# M3351 register map
File version: 1.0
Registers are 32-bit, read-write, reset 0x0 unless marked. A register's access mark holds for its fields unless they carry their own. Offsets are from the block's base; [hi:lo] are bit positions.

## I3C0 (part 1 of 2) — I3C Register Map
Base 0x40086000
Same registers: I3C0_NS 0x50086000
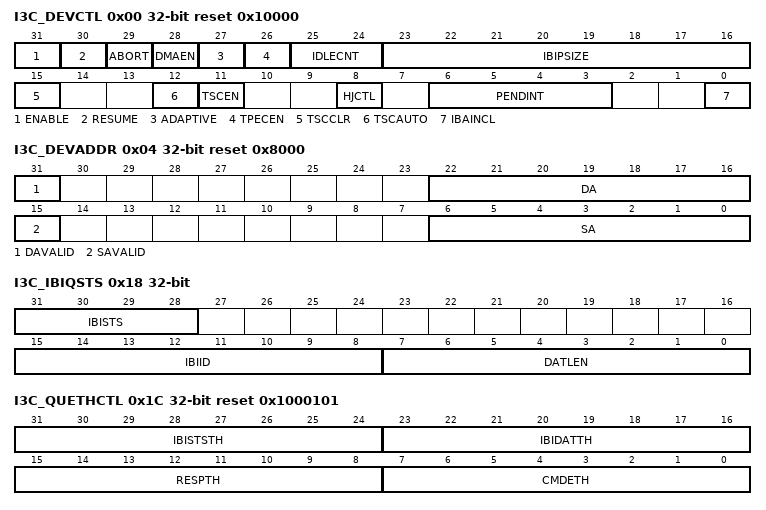
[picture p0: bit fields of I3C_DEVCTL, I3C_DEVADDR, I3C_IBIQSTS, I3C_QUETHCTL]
0x00 I3C_DEVCTL reset 0x10000 — I3C Device Control Register
  [31] ENABLE — Controls whether or not I3C is Enabled. Note 1: To Enable the Target controller, the application must set the ENABLE bit to 1. Enabling the Target controller might not be instantaneous because it is dependent on the availability of SCL clock on the I3C line. Note 2: To Disable the Target controller, the application after setting the value of 0 to the ENABLE bit must keep polling the ENABLE bit to check whether the bit value is zero. Note 3: Once the ENABLE bit is read with a value of zero, the application can be sure that the Target controller is disabled. If the SCL clock is present, the Target controller takes two SCL clocks to come out of the Disable state.
    0=I3C controller Disabled; 1=I3C controller Enabled
  [30] RESUME — I3C Resume Bit. This bit is used to resume the Controller/Target after it goes to the halt state. Note 1: In the Controller mode of operation, the Controller goes to the halt state due to any type of error in the transfer. After the Controller gones to the halt state, the application has to write 1'b1 to this bit to resume the Controller. This bit is auto-cleared once the Controller resumes the transfers by initiating the next command. Note 2: In the Target mode of operation, the Target goes to the halt state due to following conditions: Any type of error in the transfer. MRL in I3C_SLVMXLEN[31:16] updated by the controller through SETMRL CCC. After the Target goes to the halt state, the application has to take necessary action to handle the error condition and then write 1'b1 to this bit to resume the Target. This bit is auto-cleared once the Target is ready to accept new transfers (If Target has Protocol Error, RESUME bit cannot auto-clear until GETSTATS CCC is received).
    0=Resume operation is completion; 1=Resume operation is in progress
  [29] ABORT — Abort Controller Operation. This bit is used in Controller mode of operation. This bit allows the Controller to relinquish the I3C bus before completing the issued transfer In response to an ABORT request, the Controller issues the STOP condition after the complete data byte is transferred or received. This bit is auto-cleared once the transfer is aborted and the Controller issues a 'Transfer Abort' interrupt (I3C_INTSTS[5]).
    0=No effect; 1=Trigger ABORT request
  [28] DMAEN — DMA Handshake Interface Enable
    0=The DMA handshake control has no significance; 1=Enables the DMA handshake control to interact with external DMA
  [27] ADAPTIVE — Adaptive Mode. This bit is used in Target mode of operation. Setting of this bit is NOT required to put the Target in Adaptive Mode. It is only used to enable some features of the Target device to adapt to Adaptive I2C/I3C mode of operation. This bit is cleared automatically if the Target determines the mode as I3C. Effect on Hot-Join operation:
    0=The Target initiates a Hot- Join without determining the bus mode assuming itself to be on i3c bus. This bit should be set only if the Target application does not know to which bus the device is connected to.; 1=The Target initiates a Hot-Join request only after it has switched to I3C mode of operation
  [26] TPECEN — Target Packet Error Check Enable Bit. Target application to enable Packet Error Check. The user programs this bit before enabling the Target.
    0=PEC support is Disabled; 1=PEC support is Enabled
  [25:24] IDLECNT — Idle Count Multiplier. This field is used in Target mode of operation. After power-on reset, the Target device is enabled only after it sees both SDA and SCL lines idle for a specified time. This idle time is calculated by multiplying IDLECNT with AVAILTC field in BUSFAT[31:16].
  [23:16] IBIPSIZE — Target Maximum IBI Payload Size. This value reflects the I3C Target IBI Payload Size if the Controller sends a GETMRL/SETMRL CCC. Note: This field is read only.
  [15] TSCCLR — Timestamp Counter Clear Bit. This bit is used in Controller mode of operation. Note: This bit is cleared by hardware automatically.
    0=Clear timestamp counter Disabled; 1=Clear Clear timestamp counter Enabled
  [12] TSCAUTO — Timestamp Counter Automatic Enable Bit. This bit is used in Target mode of operation. When SIR is Enabled, Timestamp Counter will be cleared and restarted.
    0=Timestamp Counter automatic Disabled; 1=Timestamp Counter automatic Enabled
  [11] TSCEN — Timestamp Counter Enable Bit. This bit is used in Controller mode of operation.
    0=Timestamp counter Disabled; 1=Timestamp counter Enabled
  [8] HJCTL — Hot-Join ACK/NACK Control. This bit is used in Controller mode of operation. This bit acts as a global control to ACK/NACK the Hot-Join request from the devices. The I3C Controller ACK/NACKs the Hot-Join request from other devices connected on the I3C bus, based on programming of this bit.
    0=ACK the Hot-join request; 1=NACK and send broadcast DISEC CCC to disable Hot-Join of Target devices
  [6:3] PENDINT — Pending Interrupt Status. This field is used in Target mode of operation. This field is used for setting the interrupt number and is also reflected in I3C_CCCDEVS[3:0] PENDINT.
  [0] IBAINCL — I3C Broadcast Address Include. This bit is used in Controller mode of operation. Note: If I3C broadcast address is not included for the private transfers, In-Band Interrupts (IBI) driven from Targets might not win address arbitration. Hence, the IBIs get delayed.
    0=I3C Broadcast Address (0x7E) is not included for Private Transfer; 1=I3C Broadcast Address (0x7E) is included for Private Transfers
0x04 I3C_DEVADDR reset 0x8000 — I3C Device Address Register
  [31] DAVALID — Dynamic Address Valid. In I3C Controller mode, the user sets this bit to 1 as it self-assigns its dynamic address. In I3C Target mode, this bit will be set to 1 when the Main Controller assigns the dynamic address during ENTDAA, SETDASA or SETAASA mechanism. Note: This bit can be auto-clear to 0 if RSTDAA CCC is reveived.
    0=I3C Dynamic Address is invalid; 1=I3C Dynamic Address is valid
  [22:16] DA — Device Dynamic Address. In Controller mode, the user has to program the Dynamic Address through the Target interface as it self-assigns its Dynamic Address. In Target mode, this field is used to indicate the device Dynamic Address after Target completes the dynamic address assignment operation by ENTDAA, SETDASA, SETAASA or SETNEDA CCC.
  [15] SAVALID — Static Address Valid. In Target mode of operation, this bit reflects whether the value of the static address is valid or not.
    0=Static Address is invalid; 1=Static Address is valid
  [6:0] SA — Device Static Address. The Target device uses this address to respond to SETDASA or SETAASA CCC to get the Dynamic Address or performs Legacy I2C Read/Write operation.
0x0C I3C_CMDQUE wo — I3C Command Queue Port Register
  [31:0] CMDQUE — Command Queue. This field is used in Controller mode of operation. Please refer to chapter Controller Command Data Structure.
0x10 I3C_RESPQUE ro — I3C Response Queue Port Register
  [31:0] RESPQUE — Response Queue. Please refer to chapter Controller Response Data Structure and chapter Extended Response Data Structure.
0x14 I3C_TXRXDAT — I3C Transmit and Receive Data Port Register
  [31:0] DAT — Transmit and Receive Data Port. Transmit (Write) Operation: The transmit operation is used in Controller mode of operation. The Transmit Data port is mapped to the Tx-Data Buffer. The transmit data should always be packed as 4-byte aligned data words and written to the Transmit Data Port register. If the Command length is not aligned to 4-bytes, then the additional bytes are ignored. Receive (Read) Operation: The receive operation is used in both Controller mode and Target mode. The Receive Data port is mapped to the Rx-Data Buffer. The receive data is always packed in 4-byte aligned data words and stored in the Rx-Data Buffer. If the command length is not aligned to the 4-bytes, then the additional data bytes have to be ignored.
0x18 I3C_IBIQSTS ro — I3C Controller In-Band Interrupt Queue Status Register
  [31:28] IBISTS — IBI Received Status. Defines the Controller response for IBI received.
  [15:8] IBIID — IBI Identifier. The byte received after START which includes the address and the R/W bit. Device address and R/W bit in case of Target Interrupt or Controller Request. Hot-Join ID (0x2) and R/W bit in case of Hot-Join request.
  [7:0] DATLEN — In-Band Interrupt Data Length. This field represents the length of data received along with the IBI, in bytes.
0x18 I3C_IBIQUE ro (alternate view of I3C_IBIQSTS) — I3C Controller In-Band Interrupt Queue Data Register
  [31:0] IBIDAT — In-Band Interrupt Data. This register when read from, reads the data from the IBI Queue. This register is mapped to the IBI Queue. The IBI Data is always packed in 4-byte aligned and put to the IBI Queue. If the incoming data is not aligned to the 4-bytes, then there are unused bytes in the end location of the IBI transfer.
0x1C I3C_QUETHCTL reset 0x1000101 — I3C Queue Threshold Control Register
  [31:24] IBISTSTH — In-Band Interrupt Status Threshold Value. Every In-Band Interrupt received by I3C Controller generates an IBI status. The valid range is 0 to 3. This field controls the number of IBI status entries (or greater) in the IBI queue that trigger the IBITH (I3C_INTSTS[2]) interrupt. The user programs only valid values. A value of 0 sets the threshold for 1 entry, and a value of N sets the threshold for N+1 entries.
  [23:16] IBIDATTH — IBI Data Threshold Value. This field represents the IBI data segment size in DWORDS, 4 bytes. The valid range is 0 to 15. The minimum supported segment size is 1 (4 bytes) and the maximum supported size is 16 (64 bytes). The IBIDATTH field enables the slicing of the incoming IBI data and generate individual status and thereby promotes the cut-through operation in reading out the IBI data.
  [15:8] RESPTH — Response Buffer Threshold Value. Controls the number of entries (or greater) in the Response Queue that trigger the RESPRDY (I3C_INTSTS[4]) interrupt. The valid range is 0 to 3. The user programs only valid values. A value of 0 sets the threshold for 1 entry, and a value of N sets the threshold for N+1 entries.
  [7:0] CMDETH — Command Buffer Empty Threshold Value. Controls the number of empty locations (or greater) in the Command Queue that trigger CMDRDY (I3C_INTSTS[3]) interrupt. The valid range is 0 to 7. The user programs only valid values. Value of N ranging from 1 to 7 sets the threshold to N empty locations and a value of 0 sets the threshold to indicate that the queue is completely empty.
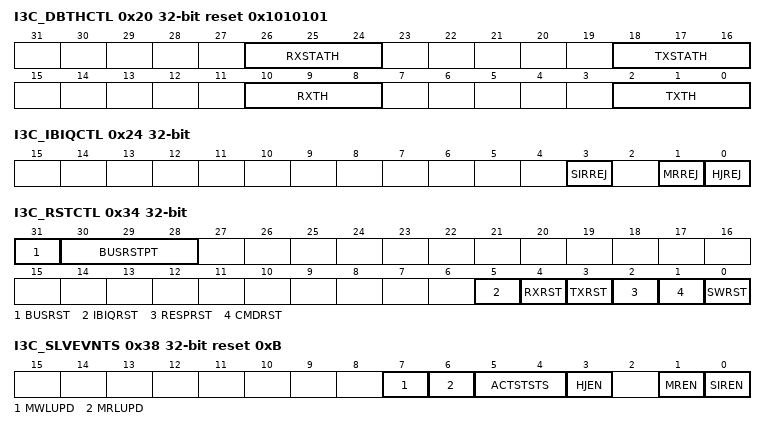
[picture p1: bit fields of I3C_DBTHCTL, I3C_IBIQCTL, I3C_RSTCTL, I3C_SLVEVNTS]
0x20 I3C_DBTHCTL reset 0x1010101 — I3C Data Buffer Threshold Control Register
  [26:24] RXSTATH — Receive Start Threshold Value. In Controller mode of operation. When the Controller is set up to initiate a read transfer, it waits until either one of the conditions are met before it initiates the read transfer on the I3C Interface. Data length (as specified in the command) number of locations are empty in the Receive FIFO. Threshold number of locations (or more) are empty in the Receive FIFO. In Target mode of operation. The Target ACK's a write request from Controller only if threshold number of empty locations (or more) are available in its receive buffer. The supported values for RXSTATH are: Note: Unit in DWORDS, 4 bytes.
  [18:16] TXSTATH — Transfer Start Threshold Value. In Controller mode of operation. When the Controller is set up to initiate a write transfer, it waits until either one of the following conditions are met before it initiates the write transfer on the I3C Interface. Data length (as specified in the command) number of locations are filled in the Transmit FIFO. Threshold number of entries (or more) are available in the Transmit FIFO. In Target mode of operation. The Target ACK's a read request from Controller only if either one of the following conditions are met: Data length (as specified in the command) number of locations are filled in the Transmit FIFO. Threshold number of entries (or more) are available in the Transmit FIFO. The supported values for TXSTATH are: Note: Unit in DWORDS, 4 bytes.
  [10:8] RXTH — Receive Buffer Threshold Value. This field controls the number of entries (or above) in the Receive FIFO that trigger the RXTH (I3C_INTSTS[1]) interrupt. The supported values for RXTH are: Note: Unit in DWORDS, 4 bytes.
  [2:0] TXTH — Transmit Buffer Threshold Value. This field controls the number of empty locations (or above) in the Transmit FIFO that trigger the TXTH (I3C_INTSTS[0]) interrupt. The supported values for TXTH are: Note: Unit in DWORDS, 4 bytes.
0x24 I3C_IBIQCTL — I3C Controller In-Band Interrupt Queue Control Register
  [3] SIRREJ — Notify Rejected Target Interrupt Request Control. This bit is used to suppress reporting to the application about SIR request rejected.
    0=Notify SIR Rejected Disabled; 1=Notify SIR Rejected Enabled
  [1] MRREJ — Notify Rejected Controller Request Control. This bit is used to suppress reporting to the application about Controller request rejected.
    0=Notify Controller Request Rejected Disabled; 1=Notify Controller Request Rejected Enabled
  [0] HJREJ — Notify Rejected Hot-Join Request Control. This bit is used to suppress reporting to the application about Hot-Join request rejected.
    0=Notify Hot-Join Request Rejected Disabled; 1=Notify Hot-Join Request Rejected Enabled
0x34 I3C_RSTCTL — I3C Reset Control Register
  [31] BUSRST — Bus Reset. This bit is used in Controller mode of operation. Note: This bit is cleared automatically once the Bus Reset Pattern Generation is completed.
    0=No effect; 1=Perform Bus Reset Pattern Generation based on Bus Reset Type (BUSRSTY) selection
  [30:28] BUSRSTPT — Bus Reset Pattern Type. This field is used in Controller mode of operation. Type of bus reset pattern triggered by BUSRST.
  [5] IBIQRST — IBI Queue Software Reset. This bit is used in Controller mode of operation. Note: This bit is cleared automatically once the IBI Queue reset is completed.
    0=No effect; 1=Perform IBI Queue reset
  [4] RXRST — Receive Buffer Software Reset. Note: This bit is cleared automatically once the Receive buffer reset is completed.
    0=No effect; 1=Perform Receive Buffer reset
  [3] TXRST — Transmit Buffer Software Reset. Note: This bit is cleared automatically once the Transmit Buffer reset is completed.
    0=No effect; 1=Perform Transmit Buffer reset
  [2] RESPRST — Response Queue Software Reset. Note: This bit is cleared automatically once the Response Queue reset is completed.
    0=No effect; 1=Perform Response Queue reset
  [1] CMDRST — Command Queue Software Reset. Note: This bit is cleared automatically once the Command Queue reset is completed.
    0=No effect; 1=Perform Command Queue reset
  [0] SWRST — Core Software Reset. This reset: The Queues and Buffers. User programmable registers to reflect the Reset values. Pipelining data (if any). The state machine to Idle state. Note: This bit is cleared automatically once the core reset is completed.
    0=No effect; 1=Perform Software reset
0x38 I3C_SLVEVNTS reset 0xB — I3C Target Event Status Register
  [7] MWLUPD — MWL Updated Status. This bit indicates a SETMWL CCC is received by the Target. The updated MWL value can be read from MWL (I3C_SLVMXLEN[15:0]). Note: This bit is cleared by writing 1 to it.
    0=SETMWL CCC not Received; 1=SETMWL CCC Received
  [6] MRLUPD — MRL Updated Status. This bit indicates a SETMRL CCC is received by the Target. The updated MRL value can be read from MRL (I3C_SLVMXLEN[31:16]). Note: This bit is cleared by writing 1 to it.
    0=SETMRL CCC not Received; 1=SETMRL CCC Received
  [5:4] ACTSTSTS — Activity State Status. This field reflects the Activity State of the Target set by the Controller. Note: This field is read only.
  [3] HJEN — Hot-Join Request Interrupt Enable Bit. This bit reflects whether the Hot-Join Request Interrupts are allowed on the I3C bus or not. The Target application can choose to Disable HJ Capability of the Target (if selected) by setting this bit to 0 before 'Enabling' the Target device. When done so, the Target does not initiate Hot-Join request and takes part in Address Assignment without initiating Hot-Join. If this bit is NOT set to 0 by Target application, it can be set or cleared by the I3C Controller through ENEC or DISEC CCC. Once Disabled by software, CCCs do not have any effect on this field.
    0=Hot-Join Request Interrupt function Disabled; 1=Hot-Join Request Interrupt function Enabled
  [1] MREN — Controller Request Enable Bit. This bit reflects whether the Target can initiate the Controller Request on the I3C bus or not. Usually, this bit is set or cleared by the I3C Controller through ENEC or DISEC CCC. Note: This bit is read only.
    0=Controller Request function Disabled; 1=Controller Request function Enabled
  [0] SIREN — Target Interrupt Request Enable Bit. This bit reflects whether the Target can initiate the SIR on the I3C bus or not. Usually, this bit is set or cleared by the I3C Controller through ENEC or DISEC CCC. Note: This bit is read only.
    0=Target Interrupt Request function Disabled; 1=Target Interrupt Request function Enabled
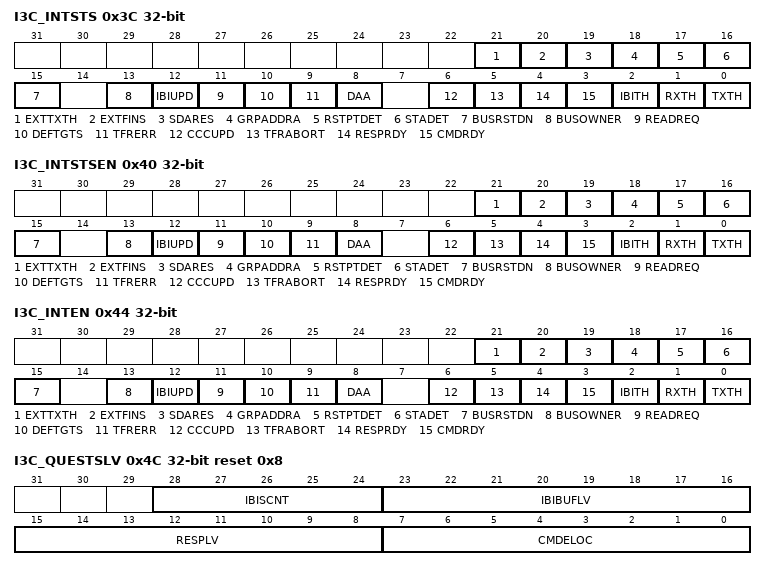
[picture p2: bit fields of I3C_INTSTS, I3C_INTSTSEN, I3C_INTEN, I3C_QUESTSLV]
0x3C I3C_INTSTS — I3C Interrupt Status Register
  [21] EXTTXTH — EXTCMD Transmit Buffer Threshold Status. This bit is used in Target mode of operation. Note 1: This bit is read only. Note 2: This bit is cleared automatically when number of empty locations in all the EXTCMD transmit buffers is less than threshold value specified.
    0=The number of EXTCMD transmit buffer empty locations is less than threshold value TXEBTH (I3C_EXTTHLD[18:16]); 1=The number of EXTCMD transmit buffer empty locations is greater than or equal to threshold value TXEBTH (I3C_EXTTHLD[18:16])
  [20] EXTFINS — EXTCMD Has Finished Status. This bit is used in Target mode of operation. This bit is generated if Read Transfer has finished (I3C_EXTCMDFS[7:0] not equal to 0) by the EXTCMD. Note 1: This bit is read only. Note 2: This bit is cleared automatically when I3C_EXTCMDFS register is read.
    0=No EXTCMD finished the transfer. (I3C_EXTCMDFS[7:0] is equal to 0); 1=EXTCMD Read Transfer has finished. (I3C_EXTCMDFS[7:0] is not equal to 0)
  [19] SDARES — SDA Released From Stuck State Status. This bit is used in Target mode of operation. This bit is generated if the SCL was not changed for the prescribed amount of time defined by RELSDATC (I3C_RELSDA[19:0]). Note: This bit is cleared by writing 1 to it.
    0=Bus in Idle state; 1=SDA status is released from stuck state
  [18] GRPADDRA — Group Address Assigned Status. This bit is used in Target mode of operation. This bit is generated if one of the Target's Group Address is assigned through SETGRPA CCC or reset through RSTGRPA CCC. Note: This bit is cleared by writing 1 to it.
    0=Group Address Assigned status no Changed; 1=Group Address Assigned status Changed
  [17] RSTPTDET — Target Reset Pattern Detection Status. This bit is used in Target mode of operation. This bit is generated when the Target Reset Pattern is detected. Note: This bit is cleared by writing 1 to it.
    0=Target Reset Pattern no Detected; 1=Target Reset Pattern Detected
  [16] STADET — START Detection Status. This bit is used in Target mode of operation. This bit is provided for the Target application to determine whether a START signal is detected on the bus. Note: This bit is cleared by writing 1 to it.
    0=START signal no Detected; 1=START signal Detected
  [15] BUSRSTDN — Bus Reset Pattern Generation Done Status. This bit is used in Controller mode of operation. This bit is generated when the Bus Reset Pattern Generation is completed. Note: This bit is cleared by writing 1 to it.
    0=Bus Reset Pattern Generation is not complete; 1=Bus Reset Pattern Generation is complete
  [13] BUSOWNER — Bus Owner Updated Status. This bit is set when the role of the device changes from being a Controller to Target or vice versa. Note 1: This bit is cleared by writing 1 to it. Note 2: The new Bus Owner value is updated only if the device's RESUME (I3C_DEVCTL[30]) bit is set.
    0=Bus Owner status is not changed; 1=Bus Owner status is changed
  [12] IBIUPD — IBI Status Updated Status. This bit is used in Target mode of operation. It indicates that the IBI request initiated through SIR register is addressed and status is updated. Note: This bit is cleared by writing 1 to it.
    0=IBI status is not updated; 1=IBI status is updated
  [11] READREQ — Read Request Received Status. This bit is used in Target mode of operation. Read Request received from the current Controller when EXTCMD is empty. Note: This bit is cleared by writing 1 to it.
  [10] DEFTGTS — DEFTGTS CCC Received Status. This bit is used in Secondary Controller mode of operation. Note: This bit is cleared by writing 1 to it.
    0=DEFTGTS (DEFSLVS) CCC is not received; 1=DEFTGTS (DEFSLVS) CCC is received
  [9] TFRERR — Transfer Error Status. This bit is generated if any error occurs during transfer. The error type is specified in the response packet associated with the command, ERRSTS field in Response Quene Port register. In Controller mode of operation, ERRSTS in I3C_RESPQUE[31:28]. In Target mode of operation, ERRSTS in I3C_RESPQUE[11:8]. Note: This bit is cleared by writing 1 to it.
    0=Transfer error is not occurred; 1=Transfer error occurred
  [8] DAA — Dynamic Address Assigned Status. This bit is used in Target mode of operation. This bit is generated if the Target Dynamic Address is assigned through ENTDAA, SETDASA, SETNEWDA or SETAASA CCC. Note: This bit is cleared by writing 1 to it.
    0=Dynamic Address is not assigned; 1=Dynamic Address is assigned
  [6] CCCUPD — CCC Table Updated Status. This bit is used in Target mode of operation. This bit is generated if any of the CCC registers are updated by I3C Controller through CCC commands. Note: This bit is cleared by writing 1 to it.
    0=Related CCC registers are not updated; 1=Related CCC registers are updated
  [5] TFRABORT — Transfer Abort Status. This bit is used in Controller mode of operation. This bit is generated if transfer is aborted. Note: This bit is cleared by writing 1 to it.
    0=Transfer is not aborted; 1=Transfer is aborted
  [4] RESPRDY — Response Queue Ready Status. This bit is generated when number of entries in response queue is greater than or equal to threshold value specified by RESPTH (I3C_QUETHCTL[15:8]). Note 1: This bit is read only. Note 2: This bit is cleared automatically when number of entries in response buffer is less than threshold value specified.
    0=Response Queue is not ready; 1=Response Queue is ready
  [3] CMDRDY — Command Queue Ready Status. This bit is used in Controller mode of operation. This bit is generated when number of empty locations in command queue is greater than or equal to threshold value specified by CMDETH (I3C_QUETHCTL[7:0]). Note 1: This bit is read only. Note 2: This bit is cleared automatically when number of empty locations in command buffer is less than threshold value specified.
    0=Command Queue is not ready; 1=Command Queue is ready
  [2] IBITH — IBI Buffer Threshold Status. This bit is used in Controller mode of operation. This bit is generated when number of entries in IBI buffer is greater than or equal to threshold value specified by IBISTSTH (I3C_QUETHCTL[31:24]). Note 1: This bit is read only. Note 2: This bit is cleared automatically when number of entries in IBI buffer is less than threshold value specified.
    0=IBI buffer is not ready; 1=IBI buffer is ready
  [1] RXTH — Receive Buffer Threshold Status. This bit is generated when number of entries in receive buffer is greater than or equal to threshold value specified by RXTH (I3C_DBTHCTL[10:8]). Note 1: This bit is read only. Note 2: This bit is cleared automatically when number of entries in receive buffer is less than threshold value specified.
    0=The number of receive buffer is less than to threshold value specified by RXTH; 1=The number of receive buffer is greater than or equal to threshold value specified by RXTH
  [0] TXTH — Transmit Buffer Threshold Status. This bit is generated when the number of empty locations in transmit buffer is greater than or equal to threshold value specified by TXTH (I3C_DBTHCTL[2:0]). Note 1: This bit is read only. Note 2: This bit is cleared automatically when number of empty locations in transmit buffer is less than threshold value specified.
    0=The number of receive buffer is less than to threshold value specified by TXTH; 1=The number of receive buffer is greater than or equal to threshold value specified by TXTH
0x40 I3C_INTSTSEN — I3C Interrupt Status Enable Register
  [21] EXTTXTH — EXTCMD Transmit Buffer Threshold Status Enable Bit. This bit is used in Target mode of operation.
    0=EXTCMD Transmit Buffer Threshold Status Disabled; 1=EXTCMD Transmit Buffer Threshold Status Enabled
  [20] EXTFINS — EXTCMD Has Finished Status Enable Bit. This bit is used in Target mode of operation.
    0=EXTCMD Has Finished Status Disabled; 1=EXTCMD Has Finished Status Enabled
  [19] SDARES — SDA Released From Stuck Status Enable Bit. This bit is used in Target mode of operation.
    0=SDA Released From Stuck Status Disabled; 1=SDA Released From Stuck Status Enabled
  [18] GRPADDRA — Group Address Assigned Status Enable Bit. This bit is used in Target mode of operation.
    0=Group Address Assigned Status Disabled; 1=Group Address Assigned Status Enabled
  [17] RSTPTDET — Target Reset Pattern Detection Status Enable Bit. This bit is used in Target mode of operation.
    0=Target Reset Pattern Detection Status Disabled; 1=Target Reset Pattern Detection Status Enabled
  [16] STADET — START Detection Status Enable Bit. This bit is used in Target mode of operation.
    0=START Detection Status Disabled; 1=START Detection Status Enabled
  [15] BUSRSTDN — Bus Reset Pattern Generation Done Status Enable Bit. This bit is used in Controller mode of operation.
    0=Bus Reset Pattern Generation Done Status Disabled; 1=Bus Reset Pattern Generation Done Status Enabled
  [13] BUSOWNER — Bus Owner Updated Status Enable Bit. This bit is used in both Controller and Target mode of operation.
    0=Bus Owner Updated Status Disabled; 1=Bus Owner Updated Status Enabled
  [12] IBIUPD — IBI Updated Status Enable Bit. This bit is used in Target mode of operation.
    0=IBI Updated Status Disabled; 1=IBI Updated Status Enabled
  [11] READREQ — Read Request Received Status Enable Bit. This bit is used in Target mode of operation.
    0=Read Request Received Status Disabled; 1=Read Request Received Status Enabled
  [10] DEFTGTS — DEFTGTS CCC Received Status Enable Bit. This bit is used in Secondary Controller mode of operation.
    0=DEFTGTS CCC Received Status Disabled; 1=DEFTGTS CCC Received Status Enabled
  [9] TFRERR — Transfer Error Status Enable Bit. This bit is used in both Controller and Target mode of operation.
    0=Transfer Error Status Disabled; 1=Transfer Error Status Enabled
  [8] DAA — Dynamic Address Assigned Status Enable Bit. This bit is used in Target mode of operation.
    0=Dynamic Address Assigned Status Disabled; 1=Dynamic Address Assigned Status Enabled
  [6] CCCUPD — CCC Table Updated Status Enable Bit. This bit is used in Target mode of operation.
    0=CCC Table Updated Status Disabled; 1=CCC Table Updated Status Enabled
  [5] TFRABORT — Transfer Abort Status Enable Bit. This bit is used in Controller mode of operation.
    0=Transfer Abort Updated Status Disabled; 1=Transfer Abort Updated Status Enabled
  [4] RESPRDY — Response Queue Ready Status Enable Bit. This bit is used in both Controller and Target mode of operation.
    0=Response Queue Ready Status Disabled; 1=Response Queue Ready Status Enabled
  [3] CMDRDY — Command Queue Ready Status Enable Bit. This bit is used in Controller mode of operation.
    0=Command Queue Ready Status Disabled; 1=Command Queue Ready Status Enabled
  [2] IBITH — IBI Buffer Threshold Status Enable Bit. This bit is used in Controller mode of operation.
    0=IBI Buffer Threshold Status Disabled; 1=IBI Buffer Threshold Status Enabled
  [1] RXTH — Receive Buffer Threshold Status Enable Bit. This bit is used in both Controller and Target mode of operation.
    0=Receive Buffer Threshold Status Disabled; 1=Receive Buffer Threshold Status Enabled
  [0] TXTH — Transmit Buffer Threshold Status Enable Bit. This bit is used in both Controller and Target mode of operation.
    0=Transmit Buffer Threshold Status Disabled; 1=Transmit Buffer Threshold Status Enabled
0x44 I3C_INTEN — I3C Interrupt Signal Enable Register
  [21] EXTTXTH — EXTCMD Transmit Buffer Threshold Signal Enable Bit. This bit is used in Target mode of operation.
    0=EXTCMD Transmit Buffer Threshold Interrupt Disabled; 1=EXTCMD Transmit Buffer Threshold Interrupt Enabled
  [20] EXTFINS — EXTCMD Has Finished Signal Enable Bit. This bit is used in Target mode of operation.
    0=EXTCMD Has Finished Interrupt Disabled; 1=EXTCMD Has Finished Interrupt Enabled
  [19] SDARES — SDA Released From Stuck Signal Enable Bit. This bit is used in Target mode of operation.
    0=SDA Released From Stuck Interrupt Disabled; 1=SDA Released From Stuck Interrupt Enabled
  [18] GRPADDRA — Group Address Assigned Signal Enable Bit. This bit is used in Target mode of operation.
    0=Group Address Assigned Interrupt Disabled; 1=Group Address Assigned Interrupt Enabled
  [17] RSTPTDET — Target Reset Pattern Detection Signal Enable Bit. This bit is used in Target mode of operation.
    0=Target Reset Pattern Detection Interrupt Disabled; 1=Target Reset Pattern Detection Interrupt Enabled
  [16] STADET — START Detection Signal Enable Bit. This bit is used in Target mode of operation.
    0=START Detection Interrupt Disabled; 1=START Detection Interrupt Enabled
  [15] BUSRSTDN — Bus Reset Pattern Generation Done Signal Enable Bit. This bit is used in Controller mode of operation.
    0=Bus Reset Pattern Generation Done Interrupt Disabled; 1=Bus Reset Pattern Generation Done Interrupt Enabled
  [13] BUSOWNER — Bus Owner Updated Signal Enable Bit. This bit is used in both Controller and Target mode of operation.
    0=Bus Owner Updated Interrupt Disabled; 1=Bus Owner Updated Interrupt Enabled
  [12] IBIUPD — IBI Updated Signal Enable Bit. This bit is used in Target mode of operation.
    0=IBI Updated Interrupt Disabled; 1=IBI Updated Interrupt Enabled
  [11] READREQ — Read Request Received Signal Enable Bit. This bit is used in Target mode of operation.
    0=Read Request Received Interrupt Disabled; 1=Read Request Received Interrupt Enabled
  [10] DEFTGTS — DEFTGTS CCC Received Signal Enable Bit. This bit is used in Secondary Controller mode of operation.
    0=DEFTGTS CCC Received Interrupt Disabled; 1=DEFTGTS CCC Received Interrupt Enabled
  [9] TFRERR — Transfer Error Signal Enable Bit. This bit is used in both Controller and Target mode of operation.
    0=Transfer Error Interrupt Disabled; 1=Transfer Error Interrupt Enabled
  [8] DAA — Dynamic Address Assigned Signal Enable Bit. This bit is used in Target mode of operation.
    0=Dynamic Address Assigned Interrupt Disabled; 1=Dynamic Address Assigned Interrupt Enabled
  [6] CCCUPD — CCC Table Updated Signal Enable Bit. This bit is used in Target mode of operation.
    0=CCC Table Updated Interrupt Disabled; 1=CCC Table Updated Interrupt Enabled
  [5] TFRABORT — Transfer Abort Signal Enable Bit. This bit is used in Controller mode of operation.
    0=Transfer Abort Interrupt Disabled; 1=Transfer Abort Interrupt Enabled
  [4] RESPRDY — Response Queue Ready Signal Enable Bit. This bit is used in both Controller and Target mode of operation.
    0=Response Queue Ready Interrupt Disabled; 1=Response Queue Ready Interrupt Enabled
  [3] CMDRDY — Command Queue Ready Signal Enable Bit. This bit is used in Controller mode of operation.
    0=Command Queue Ready Interrupt Disabled; 1=Command Queue Ready Interrupt Enabled
  [2] IBITH — IBI Buffer Threshold Signal Enable Bit. This bit is used in Controller mode of operation.
    0=IBI Buffer Threshold Interrupt Disabled; 1=IBI Buffer Threshold Interrupt Enabled
  [1] RXTH — Receive Buffer Threshold Signal Enable Bit. This bit is used in both Controller and Target mode of operation.
    0=Receive Buffer Threshold Interrupt Disabled; 1=Receive Buffer Threshold Interrupt Enabled
  [0] TXTH — Transmit Buffer Threshold Signal Enable Bit. This bit is used in both Controller and Target mode of operation.
    0=Transmit Buffer Threshold Interrupt Disabled; 1=Transmit Buffer Threshold Interrupt Enabled
0x4C I3C_QUESTSLV ro reset 0x8 — I3C Queue Status Level Register
  [28:24] IBISCNT — IBI Status Count. This bit is used in Controller mode of operation. Contains the number of valid IBI Status entries in the IBI Status Buffer.
  [23:16] IBIBUFLV — IBI Buffer Level Value. This bit is used in Controller mode of operation. Contains the number of valid IBI Data entries in the IBI Data Buffer.
  [15:8] RESPLV — Response Buffer Level Value. Contains the number of valid data entries in the Response Buffer.
  [7:0] CMDELOC — Command Queue Empty Locations. This bit is used in Controller mode of operation. Contains the number of empty locations in the Command Buffer.
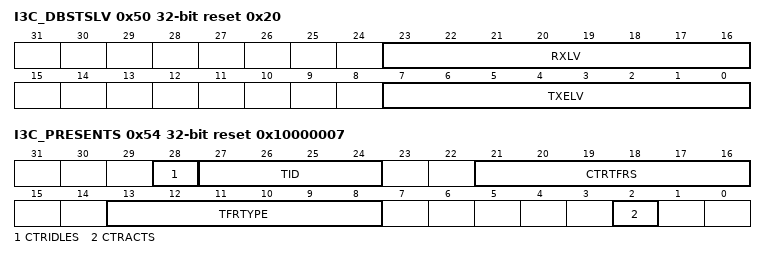
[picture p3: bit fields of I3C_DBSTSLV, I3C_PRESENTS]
0x50 I3C_DBSTSLV ro reset 0x20 — I3C Data Buffer Status Level Register
  [23:16] RXLV — Receive Buffer Level Value. Contains the number of valid data entries in the Receive Buffer.
  [7:0] TXELV — Transmit Buffer Empty Level Value. Contains the number of empty locations in the Transmit Buffer.
0x54 I3C_PRESENTS ro reset 0x10000007 — I3C Present State Register
  [28] CTRIDLES — Current Controller In IDLE State Or Not. This bit is used in Controller mode of operation. This bit is set when all the Queues (Command , Response, IBI) and Buffers (Transmit and Receive) are empty along with the Controller State machine is in IDLE state.
    0=Controller is not in IDLE State; 1=Controller is in IDLE State
  [27:24] TID — Transmit Transaction ID. This field reflects the Transaction ID of the current executing command.
  [21:16] CTRTFRS — Current Controller Transfer State Status. This bit is used in Controller mode of operation. Indicates the state of current transfer currently executing by the I3C Controller.
  [13:8] TFRTYPE — Transfer Type Status. Indicates the type of transfer currently executing by the Controller or Target. In Controller mode of operation:
  [2] CTRACTS — Current Controller Active Status. This bit is used in Controller mode of operation. This bit is used to check whether the Controller is current Controller or not. The current Controller is the Controller that owns the SCL line. The Controller is the current Controller and can initiate the transfers on the line.
    0=Controller is not current Controller; 1=Controller is current Controller
